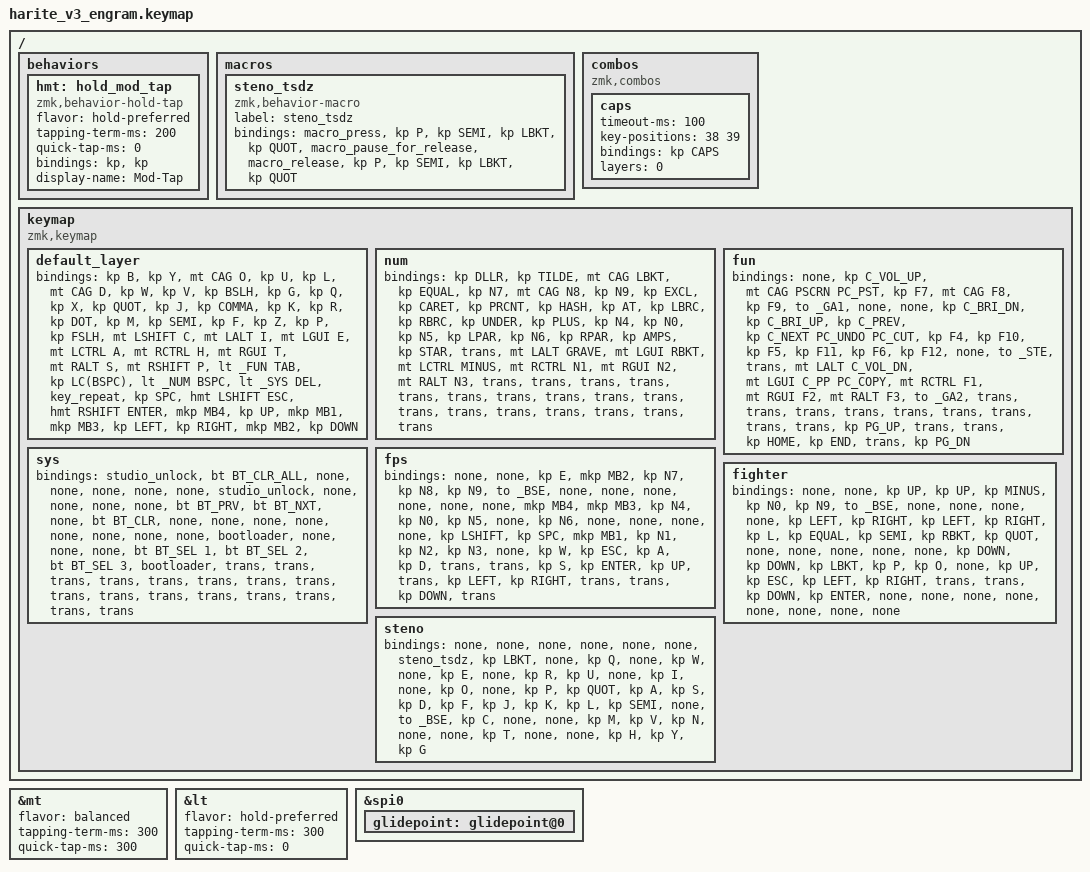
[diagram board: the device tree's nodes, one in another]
#include <behaviors.dtsi>
#include <dt-bindings/zmk/keys.h>
#include <dt-bindings/zmk/bt.h>
#include <dt-bindings/zmk/pointing.h>

// LAYERS
#define _BSE 0
#define _NUM 1
#define _FUN 2
#define _SYS 3
#define _GA1 4
#define _GA2 5
#define _STE 6

// KEYS
#define PC_UNDO &kp LC(Z)
#define PC_CUT  &kp LC(X)
#define PC_COPY &mt LCTRL LC(C)
#define PC_PST  &kp LC(V)

#define CAG LC(LA(LGUI))

&mt {
  flavor = "balanced";
  tapping-term-ms = <300>;
  quick-tap-ms = <300>;
};

&lt {
  flavor = "hold-preferred";
  tapping-term-ms = <300>;
  quick-tap-ms = <0>;
};

/ {
    behaviors {
        hmt: hold_mod_tap {
            compatible = "zmk,behavior-hold-tap";
            #binding-cells = <2>;
            flavor = "hold-preferred";
            tapping-term-ms = <200>;
            quick-tap-ms = <0>;
            bindings = <&kp>, <&kp>;
            display-name = "Mod-Tap";
        };
    };

    macros {
      /* #include "macros.dtsi" */
      steno_tsdz: steno_tsdz {
          compatible = "zmk,behavior-macro";
          label = "steno_tsdz";
          #binding-cells = <0>;
          bindings = 
              <&macro_press &kp P &kp SEMI &kp LBKT &kp QUOT>,
              <&macro_pause_for_release>,
              <&macro_release &kp P &kp SEMI &kp LBKT &kp QUOT>
          ;
      };
    };

    combos {
      compatible = "zmk,combos";
      /* #include "combos.dtsi" */
      caps {
        timeout-ms = <100>;
        key-positions = <38 39>; // Both shifts
        bindings = <&kp CAPS>;
        layers = <0>;
      };
    };

    keymap {
        compatible = "zmk,keymap";

        default_layer {
            bindings = <
                  &kp B          &kp Y        &mt CAG O       &kp U                           &kp L           &mt CAG D       &kp W        &kp V
                &kp BSLH &kp G  &kp Q &kp X  &kp QUOT &kp J  &kp COMMA &kp K                 &kp R  &kp DOT  &kp M &kp SEMI  &kp F &kp Z  &kp P &kp FSLH
                  &mt LSHIFT C   &mt LALT I   &mt LGUI E      &mt LCTRL A                     &mt RCTRL H     &mt RGUI T      &mt RALT S   &mt RSHIFT P

                                                              &lt _FUN TAB                 &kp LC(BSPC)
                                                            &lt _NUM BSPC &lt _SYS DEL    &key_repeat &kp SPC
                                                              &hmt LSHIFT ESC              &hmt RSHIFT ENTER
                                                              &mkp MB4                     &kp UP
                                                            &mkp MB1 &mkp MB3             &kp LEFT &kp RIGHT
                                                              &mkp MB2                     &kp DOWN
            >;
        };
        num {
            bindings = <
                  &kp DLLR            &kp TILDE         &mt CAG LBKT       &kp EQUAL              &kp N7        &mt CAG N8       &kp N9           &kp EXCL
                &kp CARET &kp PRCNT  &kp HASH  &kp AT  &kp LBRC &kp RBRC  &kp UNDER &kp PLUS    &kp N4 &kp N0  &kp N5 &kp LPAR  &kp N6 &kp RPAR  &kp AMPS &kp STAR
                  &trans              &mt LALT GRAVE    &mt LGUI RBKT      &mt LCTRL MINUS        &mt RCTRL N1  &mt RGUI N2      &mt RALT N3      &trans

                                                                           &trans                 &trans
                                                                         &trans  &trans         &trans  &trans
                                                                           &trans                 &trans
                                                                           &trans                 &trans
                                                                         &trans  &trans         &trans  &trans
                                                                           &trans                 &trans
            >;
        };
        fun {
            bindings = <
                 &none        &kp C_VOL_UP               &mt CAG PSCRN          PC_PST            &kp F7          &mt CAG  F8     &kp F9          &to _GA1
                &none &none  &kp C_BRI_DN &kp C_BRI_UP  &kp C_PREV &kp C_NEXT  PC_UNDO PC_CUT    &kp F4 &kp F10  &kp F5 &kp F11  &kp F6 &kp F12  &none  &to _STE
                 &trans       &mt LALT C_VOL_DN          &mt LGUI C_PP          PC_COPY           &mt RCTRL F1    &mt RGUI F2     &mt RALT F3     &to _GA2

                                                                                &trans            &trans
                                                                              &trans  &trans    &trans  &trans
                                                                                &trans            &trans
                                                                                &trans            &kp PG_UP
                                                                              &trans  &trans    &kp HOME  &kp END
                                                                                &trans            &kp PG_DN
            >;
        };
        sys {
            bindings = <
                 &studio_unlock  &bt BT_CLR_ALL  &none                  &none               &none         &none         &none         &studio_unlock
                &none &none    &none &none      &bt BT_PRV &bt BT_NXT  &none &bt BT_CLR    &none &none   &none &none   &none &none   &none &none
                 &bootloader    &none            &none                  &none               &bt BT_SEL 1  &bt BT_SEL 2  &bt BT_SEL 3  &bootloader

                                                                         &trans              &trans
                                                                       &trans  &trans      &trans  &trans
                                                                         &trans              &trans
                                                                         &trans              &trans
                                                                       &trans  &trans      &trans  &trans
                                                                         &trans              &trans
            >;
        };
        fps {
            bindings = <
                 &none         &none        &kp E        &mkp MB2              &kp N7         &kp N8        &kp N9        &to _BSE
                &none  &none  &none &none  &none &none  &mkp MB4 &mkp MB3     &kp N4 &kp N0  &kp N5 &none  &kp N6 &none  &none &none
                 &none         &kp LSHIFT   &kp SPC      &mkp MB1              &kp N1         &kp N2        &kp N3        &none

                                                         &kp W                 &kp ESC
                                                        &kp A &kp D           &trans &trans
                                                         &kp S                 &kp ENTER
                                                         &kp UP                &trans
                                                        &kp LEFT &kp RIGHT    &trans &trans
                                                         &kp DOWN              &trans
            >;
        };
        fighter {
            bindings = <
                  &none         &none        &kp UP               &kp UP                    &kp MINUS        &kp N0                &kp N9          &to _BSE
                &none  &none  &none &none  &kp LEFT  &kp RIGHT  &kp LEFT  &kp RIGHT       &kp L  &kp EQUAL  &kp SEMI &kp RBKT    &kp QUOT &none  &none  &none
                  &none         &none        &kp DOWN             &kp DOWN                  &kp LBKT            &kp P                 &kp O         &none

                                                          &kp UP               &kp ESC
                                                        &kp LEFT  &kp RIGHT &trans  &trans
                                                          &kp DOWN             &kp ENTER
                                                          &none             &none
                                                        &none  &none     &none  &none
                                                          &none             &none
            >;
        };
        steno {
            bindings = <
                  &none         &none        &none        &none              &none         &none          &steno_tsdz               &kp LBKT
                &none  &kp Q  &none &kp W  &none &kp E  &none  &kp R       &kp U  &none  &kp I   &none  &kp O  &none  &kp P  &kp QUOT
                  &kp A         &kp S        &kp D        &kp F              &kp J         &kp K          &kp L               &kp SEMI

                                                          &none             &to _BSE
                                                        &kp C  &none     &none  &kp M
                                                          &kp V             &kp N
                                                          &none             &none
                                                        &kp T  &none     &none  &kp H
                                                          &kp Y             &kp G
            >;
        };
        /*
        new {
            bindings = <
                  &none         &none        &none        &none              &none         &none          &none         &none
                &none  &none  &none &none  &none &none  &none  &none       &none  &none  &none   &none  &none  &none  &none  &none
                  &none         &none        &none        &none              &none         &none          &none         &none

                                                          &trans             &trans
                                                        &trans  &trans     &trans  &trans
                                                          &trans             &trans
                                                          &trans             &trans
                                                        &trans  &trans     &trans  &trans
                                                          &trans             &trans
            >;
        };
        */
    };

    /* Wired */
    /* wired_split { */
    /*     compatible = "zmk,wired-split"; */
    /*     device = <&xiao_serial>; */
    /* }; */

    /* Cirque */
    /* glidepoint_listener: glidepoint_listener { */
    /*     compatible = "zmk,input-listener"; */
    /*     device = <&glidepoint>; */
    /* }; */
    /* PMW3310 */
    /* trackball_listener { */
    /*   compatible = "zmk,input-listener"; */
    /*   device = <&trackball>; */
    /* }; */
    /* Thumbstick */
    /* anin0: analog_input_0 { */
    /*   compatible = "zmk,analog-input"; */
    /*   status = "disabled"; */
    /*   sampling-hz = <100>; */
    /*   x-ch { */
    /*     io-channels = <&adc 2>; */
    /*     mv-mid = <1667>; */
    /*     mv-min-max = <3738>; */
    /*     mv-deadzone = <300>; */
    /*     scale-multiplier = <1>; */
    /*     scale-divisor = <1000>; */
    /*     invert; */
    /*     evt-type = <INPUT_EV_REL>; */
    /*     input-code = <INPUT_REL_X>; */
    /*   }; */
    /*   y-ch { */
    /*     io-channels = <&adc 3>; */
    /*     mv-mid = <2055>; */
    /*     mv-min-max = <3718>; */
    /*     mv-deadzone = <300>; */
    /*     scale-multiplier = <1>; */
    /*     scale-divisor = <1000>; */
    /*     evt-type = <INPUT_EV_REL>; */
    /*     input-code = <INPUT_REL_Y>; */
    /*   }; */
    /* }; */
    /* analog_input_listener { */
    /*     status = "okay"; */
    /*     compatible = "zmk,input-listener"; */
    /*     device = <&anin0>; */
    /*     input-processors = <&zip_xy_to_scroll_mapper>; */
    /* }; */
 };

/* Cirque */
&spi0 {
    status = "okay";
    glidepoint: glidepoint@0 {
        status = "okay";
    };
};

/* PMW3310 */
/* &spi1 { */
/*     status = "okay"; */
/*     trackball: trackball@0 { */
/*         status = "okay"; */
/*     }; */
/* }; */

/* Thumbstick */
/* &adc { */
/* 	status = "okay"; */
/* }; */

